# NM1810AE_v1 register map
File version: 1.0
Registers are 32-bit, read-write, reset 0x0 unless marked. A register's access mark holds for its fields unless they carry their own. Offsets are from the block's base; [hi:lo] are bit positions; {n}, {i} and the like mark numbered series; 'fields as' and 'values as' point back to an identical list.

## EPWM — EPWM Register Map
Base 0x40040000
0x00 EPWM_NPCTL — EPWM Negative Polarity Control Register
  [5:0] NEGPOLAR — PWM Negative Polarity Control. The register bit controls polarity/active state of real PWM output.
    0=PWM_CHn output is active high; 1=PWM_CHn output is active low
0x04 EPWM_CLKDIV — EPWM Clock Select Register
  [3:0] CLKDIV — EPWM Clock Divider (9 Step Divider). Select clock input for PWM timer
    0=1 (HCLK / 2^0); 1=1/2 (HCLK / 2^1); 2=1/4 (HCLK / 2^2); 3=1/8 (HCLK / 2^3); 4=1/16 (HCLK / 2^4); 5=1/32 (HCLK / 2^5); 6=1/64 (HCLK / 2^6); 7=1/128 (HCLK / 2^7); 8=1/256 (HCLK / 2^8)
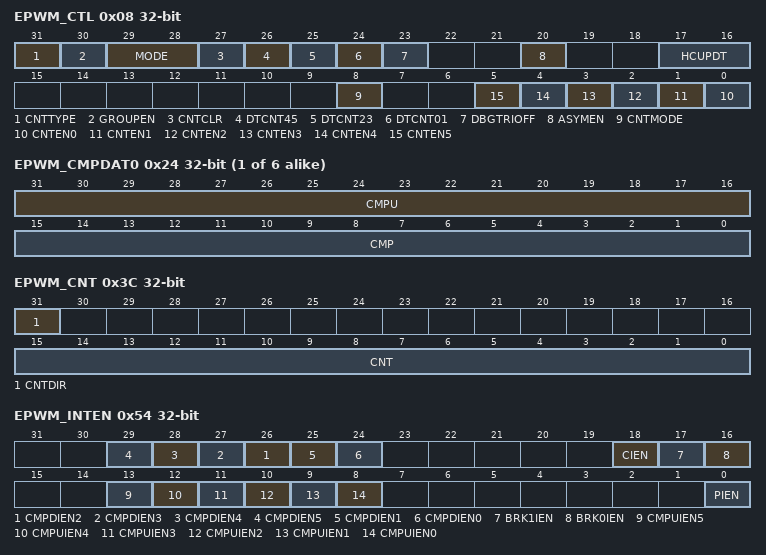
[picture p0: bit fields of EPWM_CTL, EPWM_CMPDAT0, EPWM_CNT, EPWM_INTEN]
0x08 EPWM_CTL — EPWM Control Register
  [31] CNTTYPE — PWM Aligned Type Selection Bit
    0=Edge-aligned type; 1=Center-aligned type
  [30] GROUPEN — Group Bit
    0=The signals timing of PWM0, PWM2 and PWM4 are independent; 1=Unify the signals timing of PWM0, PWM2 and PWM4 in the same phase which is controlled by PWM0
  [29:28] MODE — PWM Operating Mode Selection
    0=Independent mode; 1=Complementary mode; 2=Synchronized mode
  [27] CNTCLR — Clear PWM Counter Control Bit. Note: It is automatically cleared by hardware.
    0=Do not clear PWM counter; 1=16-bit PWM counter cleared to 0x000
  [26] DTCNT45 — Dead-zone 4 Generator Enable/Disable (PWM4 and PWM5 Pair for PWM Group). Note: When the dead-zone generator is enabled, the pair of PWM4 and PWM5 becomes a complementary pair for PWM group.
    0=Dead-zone 4 Generator Disabled; 1=Dead-zone 4 Generator Enabled
  [25] DTCNT23 — Dead-zone 2 Generator Enable/Disable (PWM2 and PWM3 Pair for PWM Group). Note: When the dead-zone generator is enabled, the pair of PWM2 and PWM3 becomes a complementary pair for PWM group.
    0=Dead-zone 2 Generator Disabled; 1=Dead-zone 2 Generator Enabled
  [24] DTCNT01 — Dead-zone 0 Generator Enable/Disable (PWM0 and PWM1 Pair for PWM Group). Note: When the dead-zone generator is enabled, the pair of PWM0 and PWM1 becomes a complementary pair for PWM group.
    0=Dead-zone 0 Generator Disabled; 1=Dead-zone 0 Generator Enabled
  [23] DBGTRIOFF — PWM Debug Mode Configuration Bit (Available in DEBUG Mode Only)
    0=Safe mode: The timer is frozen and PWM outputs are shut down Safe state for the inverter. The timer can still be re-started from where it stops; 1=Normal mode: The timer continues to operate normally May be dangerous in some cases since a constant duty cycle is applied to the inverter (no more interrupts serviced)
  [20] ASYMEN — Asymmetric Mode in Center-aligned Type
    0=symmetric mode in center-aligned type; 1=asymmetric mode in center-aligned type
  [17:16] HCUPDT — Half Cycle Update Enable for Center-aligned Type
    0=update PERIOD CMP at pwm_counter = PERIOD (Period); 1=update PERIOD CMP at pwm_counter = 0; 2=update PERIOD CMP at half cycle (counter = 0 PERIOD, both update); 3=update PERIOD CMP at pwm_counter = PERIOD (Period)
  [8] CNTMODE — PWM-timer Auto-reload/One-shot Mode
    0=One-shot mode; 1=Auto-reload mode
  [n] CNTEN{n} (n=0..5) — PWM-timer {n} Enable/Disable Start Run
    0=Corresponding PWM-timer running Stopped; 1=Corresponding PWM-timer start run Enabled
0x0C EPWM_PERIOD — EPWM Period Counter Register
  [15:0] PERIOD — PWM Counter/Timer Loaded Value. PERIODn determines the PWM Period. Edge-aligned mode: where xy, could be 01, 23, 45 depending on the selected PWM channel. Note: Any write to PERIODn will take effect in next PWM cycle.
{0x24+4i} EPWM_CMPDAT{i} (i=0..5) — EPWM Comparator Register 0
  [31:16] CMPU — PWM Comparator Register for UP Counter in Center-aligned Asymmetric Mode. CMPU PERIOD: @ up counter PWM output is keep to Max. duty.
  [15:0] CMP — PWM Comparator Register. CMP determines the PWM Duty. Edge-aligned mode: where xy, could be 01, 23, 45 depending on the selected PWM channel. Note: Any write to CMPn will take effect in next PWM cycle.
0x3C EPWM_CNT ro — EPWM Counter Register
  [31] CNTDIR — PWM Counter (Up/Down) Direction
    0=PWM counter is down count; 1=PWM counter is up count
  [15:0] CNT — PWM Counter Register. User can monitor CNT to know the current value in 16-bit down counter.
0x54 EPWM_INTEN — EPWM Interrupt Enable Register
  [n+24] CMPDIEN{n} (n=2..5) — PWM Channel {n} DOWN Interrupt Enable Bit. DOWN for Edge-aligned and Center-aligned
    0=Disable; 1=Enabled interrupt when EPWM_CH{n} PWM DOWN counter reaches CMPDAT{n}
  [25] CMPDIEN1 — PWM Channel 1 DOWN Interrupt Enable. DOWN for Edge-aligned and Center-aligned
    0=Disable; 1=Enabled interrupt when EPWM_CH1 PWM DOWN counter reaches CMPDAT1
  [24] CMPDIEN0 — PWM Channel 0 DOWN Interrupt Enable Bit. DOWN for Edge-aligned and Center-aligned
    0=Disable; 1=Enabled interrupt when EPWM_CH0 PWM DOWN counter reaches CMPDAT0
  [18] CIEN — PWM Central Interrupt Enable Bit for Center-aligned only
    0=Disable; 1=Enabled interrupt when EPWM Central
  [17] BRK1IEN — Enable Fault Brake1 Interrupt
    0=Disabling flags BKF1 to trigger PWM interrupt; 1=Enabling flags BKF1 can trigger PWM interrupt
  [16] BRK0IEN — Enable Fault Brake0 Interrupt
    0=Disabling flags BKF0 to trigger PWM interrupt; 1=Enabling flags BKF0 can trigger PWM interrupt
  [13] CMPUIEN5 — PWM Channel 5 UP Interrupt Enable Bit. UP for Center-aligned only
    0=Disable; 1=Enabled interrupt when EPWM_CH5 PWM UP counter reaches CMPDAT5
  [12] CMPUIEN4 — PWM Channel 4 UP Interrupt Enable Bit. UP for Center-aligned only
    0=Disable; 1=Enabled interrupt when EPWM_CH4 PWM UP counter reaches CMPDAT4
  [11] CMPUIEN3 — PWM Channel 3 UP Interrupt Enable. UP for Center-aligned only
    0=Disable; 1=Enabled interrupt when EPWM_CH3 PWM UP counter reaches CMPDAT3
  [10] CMPUIEN2 — PWM Channel 2 UP Interrupt Enable Bit. UP for Center-aligned only
    0=Disable; 1=Enabled interrupt when EPWM_CH2 PWM UP counter reaches CMPDAT2
  [9] CMPUIEN1 — PWM Channel 1 UP Interrupt Enable. UP for Center-aligned only
    0=Disable; 1=Enabled interrupt when EPWM_CH1 PWM UP counter reaches CMPDAT1
  [8] CMPUIEN0 — PWM Channel 0 UP Interrupt Enable. UP for Center-aligned only
    0=Disable; 1=Enabled interrupt when EPWM_CH0 PWM UP counter reaches CMPDAT0
  [0] PIEN — PWM Channel 0 Period Interrupt Enable Bit for Edge-aligned and Center-aligned
    0=Disable; 1=Enabled interrupt when EPWM Period
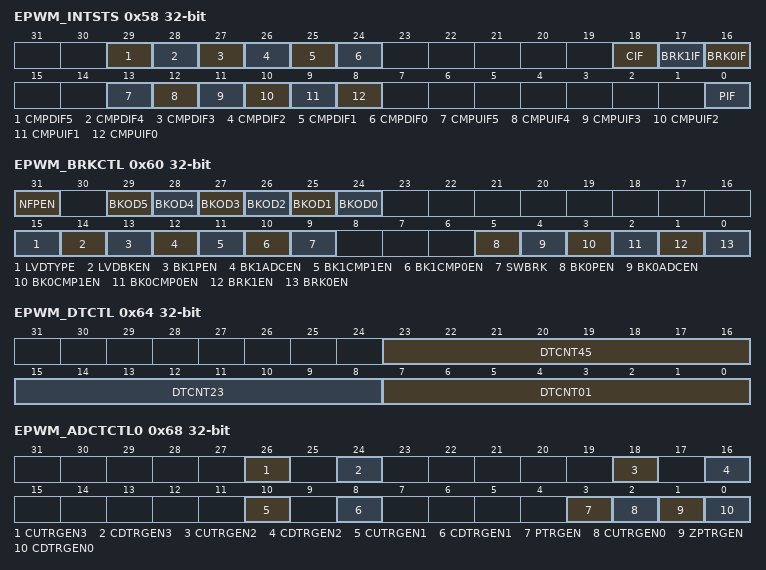
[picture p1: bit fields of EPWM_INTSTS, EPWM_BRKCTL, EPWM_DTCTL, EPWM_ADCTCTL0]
0x58 EPWM_INTSTS — EPWM Interrupt Status Register
  [29] CMPDIF5 — PWM Channel 5 DOWN Interrupt Flag. Flag is set by hardware when a channel 5 PWM DOWN counter reaches PWM_CMPDAT05. Software can write 1 to clear this bit.
  [28] CMPDIF4 — PWM Channel 4 DOWN Interrupt Flag. Flag is set by hardware when a channel 4 PWM DOWN counter reaches PWM_CMPDAT04. Software can write 1 to clear this bit.
  [27] CMPDIF3 — PWM Channel 3 DOWN Interrupt Flag. Flag is set by hardware when a channel 3 PWM DOWN counter reaches PWM_CMPDAT03. Software can write 1 to clear this bit.
  [26] CMPDIF2 — PWM Channel 2 DOWN Interrupt Flag. Flag is set by hardware when a channel 2 PWM DOWN counter reaches PWM_CMPDAT2. Software can write 1 to clear this bit.
  [25] CMPDIF1 — PWM Channel 1 DOWN Interrupt Flag. Flag is set by hardware when a channel 1 PWM DOWN counter reaches PWM_CMPDAT01. Software can write 1 to clear this bit.
  [24] CMPDIF0 — PWM Channel 0 DOWN Interrupt Flag. Flag is set by hardware when a channel 0 PWM DOWN counter reaches PWM_CMPDAT0. Software can write 1 to clear this bit.
  [18] CIF — PWM Channel 0 Central Interrupt Flag. Flag is set by hardware when a channel 0 PWM rise counter reaches PWM_PERIOD0. Software can write 1 to clear this bit.
  [17] BRK1IF — PWM Brake1 Flag. Note: Software can write 1 to clear this bit.
    0=PWM Brake does not recognize a falling signal at BKP0; 1=When PWM Brake detects a falling signal at pin BKP0, this flag will be set to high
  [16] BRK0IF — PWM Brake0 Flag. Note: Software can write 1 to clear this bit.
    values as BRK1IF
  [13] CMPUIF5 — PWM Channel 5 UP Interrupt Flag. Flag is set by hardware when a channel 5 PWM UP counter reaches PWM_CMPDAT05. Software can write 1 to clear this bit.
  [12] CMPUIF4 — PWM Channel 4 UP Interrupt Flag. Flag is set by hardware when a channel 4 PWM UP counter reaches PWM_CMPDAT04. Software can write 1 to clear this bit.
  [11] CMPUIF3 — PWM Channel 3 UP Interrupt Flag. Flag is set by hardware when a channel 3 PWMUP counter reaches PWM_CMPDAT03. Software can write 1 to clear this bit.
  [10] CMPUIF2 — PWM Channel 2 UP Interrupt Flag. Flag is set by hardware when a channel 2 PWM UP counter reaches PWM_CMPDAT02. Software can write 1 to clear this bit.
  [9] CMPUIF1 — PWM Channel 1 UP Interrupt Flag. Flag is set by hardware when a channel 1 PWM UP counter reaches PWM_CMPDAT01. Software can write 1 to clear this bit.
  [8] CMPUIF0 — PWM Channel 0 UP Interrupt Flag. Flag is set by hardware when a channel 0 PWM UP counter reaches PWM_CMPDAT0. Software can write 1 to clear this bit.
  [0] PIF — PWM Channel 0 Period Interrupt Flag. Flag is set by hardware when PWM_PERIOD0down counter reaches zero. Software can write 1 to clear this bit.
0x5C EPWM_RESDLY — EPWM BRK Low Voltage Detect Resume Delay
  [11:0] DELAY — PWM BRK Low Voltage Detect Resume Delay. 12 bits Down-Counter
0x60 EPWM_BRKCTL — EPWM Fault Brake Control Register
  [31] NFPEN — Noise Filter for External Brake Input Pin (BRK_I) Enable
    0=Disable; 1=Enable
  [n+24] BKOD{n} (n=0..5) — PWM Channel {n} Brake Output Select Register
    0=PWM output low when fault brake conditions asserted; 1=PWM output high when fault brake conditions asserted
  [15] LVDTYPE — Low-level Detection Resume Type
    0=Brake resume at BRK resume delay counter counting to 0; 1=Brake resume at period edge
  [14] LVDBKEN — Low-level Detection Trigger PWM Brake Function 1 Enable
    0=Brake Function 1 triggered by Low-level detection Disabled; 1=Brake Function 1 triggered by Low-level detection Enabled
  [13] BK1PEN — BRK1 Source From External Pin Enable
    0=Disabled; 1=Enabled
  [12] BK1ADCEN — BRK1 Source From ADC Enable
    0=Disabled; 1=Enabled
  [11] BK1CMP1EN — BRK1 Source From ACMP1 Enable
    0=Disabled; 1=Enabled
  [10] BK1CMP0EN — BRK1 Source From ACMP0 Enable
    0=Disabled; 1=Enabled
  [9] SWBRK — Software Break
    0=disable Software break and back to normal PWM function; 1=issue Software break
  [5] BK0PEN — BRK0 Source From External Pin Enable
    0=Disabled; 1=Enabled
  [4] BK0ADCEN — BRK0 Source From ADC Enable
    0=Disabled; 1=Enabled
  [3] BK0CMP1EN — BRK0 Source From ACMP1 Enable
    0=Disabled; 1=Enabled
  [2] BK0CMP0EN — BRK0 Source From ACMP0 Enable
    0=Disabled; 1=Enabled
  [1] BRK1EN — Enable BKP1 Pin Trigger Fault Brake Function 1
    0=Disabling BKP1 pin can trigger brake function 1; 1=Enabling a falling at BKP1 pin can trigger brake function 1
  [0] BRK0EN — Enable BKP0 Pin Trigger Fault Brake Function 0
    values as BRK1EN
0x64 EPWM_DTCTL — EPWM Dead-zone Interval Register
  [23:16] DTCNT45 — Dead-zone Interval Register for Pair of Channel4 and Channel5 (PWM4 and PWM5 Pair). These 8 bits determine dead-zone length. The unit time of dead-zone length is received from corresponding PWM_CLKDIV bits.
  [15:8] DTCNT23 — Dead-zone Interval Register for Pair of Channel2 and Channel3 (PWM2 and PWM3 Pair). These 8 bits determine dead-zone length. The unit time of dead-zone length is received from corresponding PWM_CLKDIV bits.
  [7:0] DTCNT01 — Dead-zone Interval Register for Pair of Channel0 and Channel1 (PWM0 and PWM1 Pair). These 8 bits determine dead-zone length. The unit time of dead-zone length is received from corresponding PWM_CLKDIV bits.
0x68 EPWM_ADCTCTL0 — EPWM Trigger ADC Control Register 0
  [all] fields
    0=Disabled; 1=Enabled
  [26] CUTRGEN3 — Enable PWM Trigger ADC Function While Channel3's Counter Matching CMP3 in Up-count Direction. Note: This bit is only valid for PWM in center aligned mode. When PWM is in edged aligned mode, setting this bit is meaningless and will not take any effect.
  [24] CDTRGEN3 — Enable PWM Trigger ADC Function While Channel3's Counter Matching CMP3 in Down-count Direction. Note: This bit is valid for both center aligned mode and edged aligned mode.
  [18] CUTRGEN2 — Enable PWM Trigger ADC Function While Channel2's Counter Matching CMP2 In Up-count Direction. Note: This bit is only valid for PWM in center aligned mode. When PWM is in edged aligned mode, setting this bit is meaningless and will not take any effect.
  [16] CDTRGEN2 — Enable PWM Trigger ADC Function While Channel2's Counter Matching CMP2 in Down-count Direction. Note: This bit is valid for both center aligned mode and edged aligned mode.
  [10] CUTRGEN1 — Enable PWM Trigger ADC Function While Channel1's Counter Matching CMP1 In Up-count Direction. Note: This bit is only valid for PWM in center aligned mode. When PWM is in edged aligned mode, setting this bit is meaningless and will not take any effect.
  [8] CDTRGEN1 — Enable PWM Trigger ADC Function While Channel1's Counter Matching CMP1 in Down-count Direction. Note: This bit is valid for both center aligned mode and edged aligned mode.
  [3] PTRGEN — Enable PWM Trigger ADC Function While Channel0's Counter Matching Period. Note: This bit is valid for both center aligned mode and edged aligned mode.
  [2] CUTRGEN0 — Enable PWM Trigger ADC Function While Channel0's Counter Matching PWM_CMPDAT0in Up-count Direction. Note: This bit is only valid for PWM in center aligned mode. When PWM is in edged aligned mode, setting this bit is meaningless and will not take any effect.
  [1] ZPTRGEN — Enable PWM Trigger ADC Function While Channel0's Counter Matching 0 (Zero Point). Note: This bit is only valid for PWM in center aligned mode. When PWM is in edged aligned mode, setting this bit is meaningless and will not take any effect.
  [0] CDTRGEN0 — Enable PWM Trigger ADC Function While Channel0's Counter Matching PWM_CMPDAT0in Down-count Direction. Note: This bit is valid for both center aligned mode and edged aligned mode.
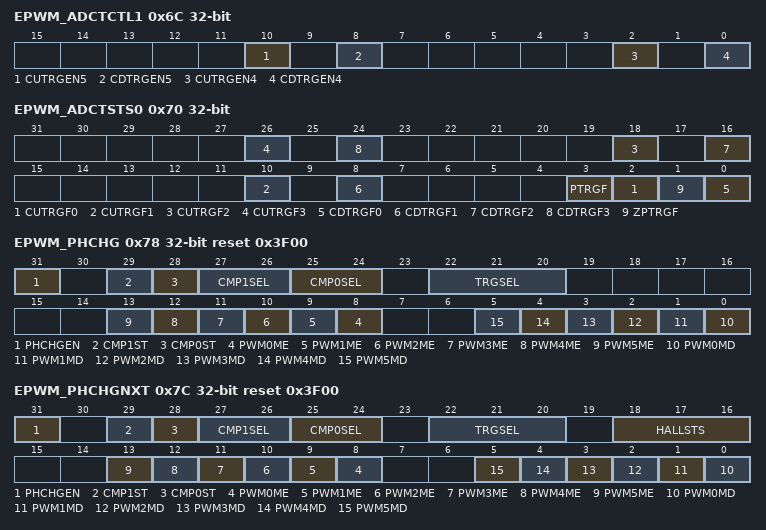
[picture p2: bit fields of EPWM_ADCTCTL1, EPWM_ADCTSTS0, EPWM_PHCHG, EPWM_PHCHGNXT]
0x6C EPWM_ADCTCTL1 — EPWM Trigger ADC Control Register 1
  [all] fields
    0=Disabled; 1=Enabled
  [10] CUTRGEN5 — Enable PWM Trigger ADC Function While Channel5's Counter Matching CMP5 in Up-count Direction. Note: This bit is only valid for PWM in center aligned mode. When PWM is in edged aligned mode, setting this bit is meaningless and will not take any effect.
  [8] CDTRGEN5 — Enable PWM Trigger ADC Function While Channel5's Counter Matching CMP5 in Down-count Direction. Note: This bit is valid for both center aligned mode and edged aligned mode.
  [2] CUTRGEN4 — Enable PWM Trigger ADC Function While Channel4's Counter Matching CMP4 in Up-count Direction. Note: This bit is only valid for PWM in center aligned mode. When PWM is in edged aligned mode, setting this bit is meaningless and will not take any effect.
  [0] CDTRGEN4 — Enable PWM Trigger ADC Function While Channel4's Counter Matching CMP4 in Down-count Direction. Note: This bit is valid for both center aligned mode and edged aligned mode.
0x70 EPWM_ADCTSTS0 — EPWM Trigger ADC Status Register 0
  [8n+2] CUTRGF{n} (n=0..3) — ADC Trigger Flag by Counting Up to CMP. Note: Software can write 1 to clear this bit.
  [8n] CDTRGF{n} (n=0..3) — ADC Trigger Flag by Counting Down to CMP. Note: Software can write 1 to clear this bit.
  [3] PTRGF — ADC Trigger Flag by Period. Note: Software can write 1 to clear this bit.
  [1] ZPTRGF — ADC Trigger Flag By Counting to 0 (Zero Point). Note: Software can write 1 to clear this bit.
0x74 EPWM_ADCTSTS1 — EPWM Trigger ADC Status Register 1
0x78 EPWM_PHCHG reset 0x3F00 — EPWM Phase Changed Register
  [31] PHCHGEN — Enable Auto Phase Change Function
    0=Auto Phase Change Function Disabled; 1=Auto Phase Change Function Enabled
  [29] CMP1ST — Start CMP1 Compare Function
    0=Disable CMP1; 1=Start CMP1
  [28] CMP0ST — Start CMP0 Compare Function
    0=Disable CMP0; 1=Start CMP0
  [27:26] CMP1SEL — Alternative Comparator 1 Positive Input Selection. Select the positive input source of ACMP1.
    0=Select ACMP1_P0 (PC.0) as the input of ACMP1; 1=Select ACMP1_P1 (PC.1) as the input of ACMP1; 2=Select ACMP1_P2 (PD.1) as the input of ACMP1
  [25:24] CMP0SEL — Alternative Comparator 0 Positive Input Selection. Select the positive input source of ACMP0.
    0=Select ACMP0_P0 (PB.0) as the input of ACMP0; 1=Select ACMP0_P1 (PB.1) as the input of ACMP0; 2=Select ACMP0_P2 (PB.2) as the input of ACMP0
  [22:20] TRGSEL — Phase Change Trigger Selection. Select the trigger condition to load PHCHG from PHCHG_NXT. When the trigger condition occurs it will load PHCHG_NOW with PHCHG_NXT. Phase Change: PWM outputs are masked according with the definition of PWMx_ME and PWMx_MD in PHCHG_NOW.
    0=Triggered by Timer0 event; 1=Triggered by Timer1 event; 2=Triggered by Timer2 event; 3=Triggered by PHCHG_NXT.HALL_STATE matched hall sensor state; 4=Triggered by CMP0 event; 5=Triggered by CMP1 event
  [n+8] PWM{n}ME (n=0..5) — Enable PWM{n} Mask Function
    0=PWM{n} Mask Function Disabled; 1=PWM{n} Mask Function Enabled
  [n] PWM{n}MD (n=0..5) — Enable PWM{n} Mask Data
    0=PWM{n} state is masked with zero; 1=PWM{n} state is masked with one
0x7C EPWM_PHCHGNXT reset 0x3F00 — EPWM Next Phase Change Register
  [31] PHCHGEN — Enable Auto Phase Change Function Preset Bit. This bit will be load to bit PHCHG_EN in PHCHG_NOW when load trigger condition occurs. Refer to register PHCHG_NOW for detailed definition.
  [29] CMP1ST — Start CMP1 Compare Function Control Preset Bit. This bit will be load to bit CMP1_ST in PHCHG_NOW when load trigger condition occurs. Refer to register PHCHG_NOW for detailed definition.
  [28] CMP0ST — Start CMP0 Compare Function Control Preset Bit. This bit will be load to bit CMP0_ST in PHCHG_NOW when load trigger condition occurs. Refer to register PHCHG_NOW for detailed definition.
  [27:26] CMP1SEL — Alternative Comparator 1 Positive Input Selection Preset Bitfs. This bit field will be load to bit field CMP1SEL in PHCHG_NOW when load trigger condition occurs. Refer to register PHCHG_NOW for detailed definition.
  [25:24] CMP0SEL — Alternative Comparator 0 Positive Input Selection Preset Bits. This bit field will be load to bit field CMP0SEL in PHCHG_NOW when load trigger condition occurs. Refer to register PHCHG_NOW for detailed definition.
  [22:20] TRGSEL — Phase Change Trigger Selection Preset Bits. This bit field will be load to bit field TRGSEL in PHCHG_NOW when load trigger condition occurs. Refer to register PWM_PHCHG for detailed definition.
    values as EPWM_PHCHG.TRGSEL
  [18:16] HALLSTS — Predicted Next HALL State. This bit field indicates the predicted hall state at next commutation. the hardware will compare bits (CAP2, CAP1, CAP0) in timer 2 with HALL_STATE[2:0] when any hall state change occurs. If the comparison is matched it will trigger phase change function.
  [n+8] PWM{n}ME (n=0..5) — Enable PWM{n} Mask Function Preset Bit. This bit will be load to bit PWM{n}_ME in PHCHG_NOW when load trigger condition occurs. Refer to register PHCHG_NOW for detailed definition.
  [n] PWM{n}MD (n=0..5) — Enable PWM{n} Mask Data Preset Bit. This bit will be load to bit PWM{n}_MD in PHCHG_NOW when load trigger condition occurs. Refer to register PHCHG_NOW for detailed definition.
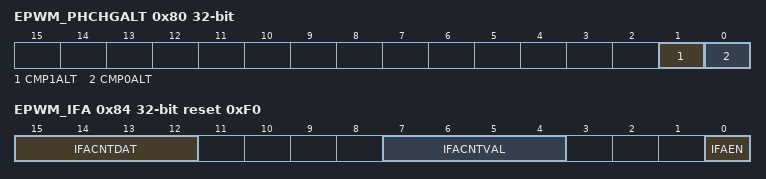
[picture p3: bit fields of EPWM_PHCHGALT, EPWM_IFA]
0x80 EPWM_PHCHGALT — EPWM Phase Change Alternative Control Register
  [1] CMP1ALT — Alternative CMP1 Positive Input Source Select. Note: Register CMP1CR is describe in Comparator Controller chapter
    0=The input of CMP1 is controlled by CMP1CR; 1=The input of CMP1 is controlled by CMP1SEL in PHCHG_NOW register
  [0] CMP0ALT — Alternative CMP0 Positive Input Source Select. Note: Register CMP0CR is describe in Comparator Controller chapter
    0=The input of CMP0 is controlled by CMP1CR; 1=The input of CMP0 is controlled by CMP1SEL in PHCHG_NOW register
0x84 EPWM_IFA reset 0xF0 — EPWM Period Interrupt Accumulation Control Register
  [15:12] IFACNTDAT ro — Period Interrupt Down-counter Data Register (Read Only). When IFAEN is set, IFACNTDAT will decrease when every PWM Interrupt flag is set, and when IFACNTDAT reach to zero, the PWM interrupt will occurred and IFACNTVAL will reload to IFACNTDAT.
  [7:4] IFACNTVAL wo — Period Interrupt Accumulation Counter Value Setting Register (Write Only). 16 step Down-Counter value setting register. When IFAEN is set, IFACNTVAL value will load into IFACNTDAT and decrase gradually.
  [0] IFAEN — Enable Period Interrupt Accumulation Function
    0=Period Interrupt Accumulation Disabled; 1=Period Interrupt Accumulation Enabled
